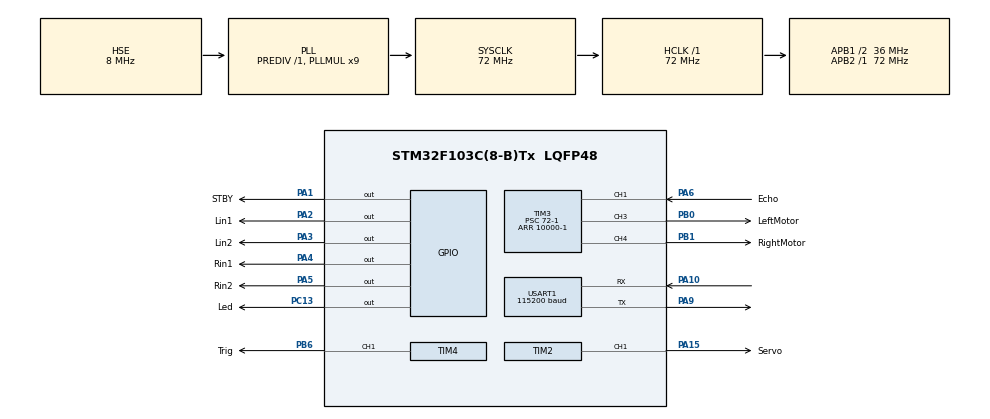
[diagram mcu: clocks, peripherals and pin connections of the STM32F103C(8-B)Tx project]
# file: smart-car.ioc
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Dma.Request0=USART1_TX
Dma.Request1=USART1_RX
Dma.USART1_RX.1.Direction=DMA_PERIPH_TO_MEMORY
Dma.USART1_RX.1.Instance=DMA1_Channel5
Dma.USART1_RX.1.MemDataAlignment=DMA_MDATAALIGN_BYTE
Dma.USART1_RX.1.MemInc=DMA_MINC_ENABLE
Dma.USART1_RX.1.Mode=DMA_NORMAL
Dma.USART1_RX.1.PeriphDataAlignment=DMA_PDATAALIGN_BYTE
Dma.USART1_RX.1.PeriphInc=DMA_PINC_DISABLE
Dma.USART1_RX.1.Priority=DMA_PRIORITY_LOW
Dma.USART1_TX.0.Direction=DMA_MEMORY_TO_PERIPH
Dma.USART1_TX.0.Instance=DMA1_Channel4
Dma.USART1_TX.0.MemDataAlignment=DMA_MDATAALIGN_BYTE
Dma.USART1_TX.0.MemInc=DMA_MINC_ENABLE
Dma.USART1_TX.0.Mode=DMA_NORMAL
Dma.USART1_TX.0.PeriphDataAlignment=DMA_PDATAALIGN_BYTE
Dma.USART1_TX.0.PeriphInc=DMA_PINC_DISABLE
Dma.USART1_TX.0.Priority=DMA_PRIORITY_LOW
FREERTOS.Tasks01=Listen,40,512,ListenInstruction,Default,NULL,Dynamic,NULL,NULL
Mcu.Family=STM32F1
Mcu.Name=STM32F103C(8-B)Tx
Mcu.Package=LQFP48
NVIC.DMA1_Channel4_IRQn=true\:6\:0\:true\:false\:true\:true\:false\:true\:true
NVIC.DMA1_Channel5_IRQn=true\:6\:0\:true\:false\:true\:true\:false\:true\:true
NVIC.PriorityGroup=NVIC_PRIORITYGROUP_4
NVIC.TIM1_UP_IRQn=true\:15\:0\:false\:false\:true\:false\:false\:true\:true
NVIC.TIM3_IRQn=true\:6\:0\:true\:false\:true\:true\:true\:true\:true
NVIC.TimeBase=TIM1_UP_IRQn
NVIC.TimeBaseIP=TIM1
NVIC.USART1_IRQn=true\:6\:0\:true\:false\:true\:true\:true\:true\:true
PA1.GPIO_Label=STBY
PA1.Signal=GPIO_Output
PA10.Mode=Asynchronous
PA10.Signal=USART1_RX
PA13.Mode=Serial_Wire
PA13.Signal=SYS_JTMS-SWDIO
PA14.Mode=Serial_Wire
PA14.Signal=SYS_JTCK-SWCLK
PA15.GPIO_Label=Servo
PA15.Signal=S_TIM2_CH1_ETR
PA2.GPIO_Label=Lin1
PA2.Signal=GPIO_Output
PA3.GPIO_Label=Lin2
PA3.Signal=GPIO_Output
PA4.GPIO_Label=Rin1
PA4.Signal=GPIO_Output
PA5.GPIO_Label=Rin2
PA5.Signal=GPIO_Output
PA6.GPIO_Label=Echo
PA6.Signal=S_TIM3_CH1
PA9.Mode=Asynchronous
PA9.Signal=USART1_TX
PB0.GPIO_Label=LeftMotor
PB0.Signal=S_TIM3_CH3
PB1.GPIO_Label=RightMotor
PB1.Signal=S_TIM3_CH4
PB6.GPIO_Label=Trig
PB6.Signal=S_TIM4_CH1
PC13-TAMPER-RTC.GPIO_Label=Led
PC13-TAMPER-RTC.Signal=GPIO_Output
PD0-OSC_IN.Mode=HSE-External-Oscillator
PD0-OSC_IN.Signal=RCC_OSC_IN
PD1-OSC_OUT.Mode=HSE-External-Oscillator
PD1-OSC_OUT.Signal=RCC_OSC_OUT
ProjectManager.HeapSize=0x200
ProjectManager.StackSize=0x400
ProjectManager.TargetToolchain=STM32CubeIDE
RCC.AHBFreq_Value=72000000
RCC.APB1CLKDivider=RCC_HCLK_DIV2
RCC.APB1Freq_Value=36000000
RCC.APB1TimFreq_Value=72000000
RCC.APB2Freq_Value=72000000
RCC.APB2TimFreq_Value=72000000
RCC.HCLKFreq_Value=72000000
RCC.PLLMUL=RCC_PLL_MUL9
RCC.PLLSourceVirtual=RCC_PLLSOURCE_HSE
RCC.SYSCLKFreq_VALUE=72000000
RCC.SYSCLKSource=RCC_SYSCLKSOURCE_PLLCLK
RCC.USBFreq_Value=72000000
SH.S_TIM2_CH1_ETR.0=TIM2_CH1,PWM Generation1 CH1
SH.S_TIM3_CH1.0=TIM3_CH1,Input_Capture1_from_TI1
SH.S_TIM3_CH3.0=TIM3_CH3,PWM Generation3 CH3
SH.S_TIM3_CH4.0=TIM3_CH4,PWM Generation4 CH4
SH.S_TIM4_CH1.0=TIM4_CH1,PWM Generation1 CH1
TIM2.Channel-PWM\ Generation1\ CH1=TIM_CHANNEL_1
TIM2.OCPolarity_1=TIM_OCPOLARITY_HIGH
TIM2.Period=2000-1
TIM2.Prescaler=720-1
TIM3.Channel-Input_Capture1_from_TI1=TIM_CHANNEL_1
TIM3.Channel-Input_Capture2_from_TI1_63=TIM_CHANNEL_2
TIM3.Channel-PWM\ Generation3\ CH3=TIM_CHANNEL_3
TIM3.Channel-PWM\ Generation4\ CH4=TIM_CHANNEL_4
TIM3.ICPolarity_CH2=TIM_INPUTCHANNELPOLARITY_FALLING
TIM3.Period=10000-1
TIM3.Prescaler=72-1
TIM4.Channel-PWM\ Generation1\ CH1=TIM_CHANNEL_1
TIM4.OCMode_PWM-PWM\ Generation1\ CH1=TIM_OCMODE_PWM2
TIM4.OCPolarity_1=TIM_OCPOLARITY_HIGH
TIM4.Period=10000 -1
TIM4.Prescaler=72 -1
TIM4.Pulse-PWM\ Generation1\ CH1=50
USART1.BaudRate=115200
USART1.VirtualMode=VM_ASYNC
VP_FREERTOS_VS_CMSIS_V2.Mode=CMSIS_V2
VP_SYS_VS_tim1.Mode=TIM1
VP_TIM3_VS_ClockSourceINT.Mode=Internal
VP_TIM3_VS_indirect_ch1.Mode=Input_Capture2_from_TI1_63
VP_TIM4_VS_OPM.Mode=OPM_bit
board=custom

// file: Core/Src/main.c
/* USER CODE BEGIN Header */
/**
  ******************************************************************************
  * @file           : main.c
  * @brief          : Main program body
  ******************************************************************************
  * @attention
  *
  * Copyright (c) 2024 STMicroelectronics.
  * All rights reserved.
  *
  * This software is licensed under terms that can be found in the LICENSE file
  * in the root directory of this software component.
  * If no LICENSE file comes with this software, it is provided AS-IS.
  *
  ******************************************************************************
  */
/* USER CODE END Header */
#include "main.h"
#include "cmsis_os.h"
#include "dma.h"
#include "tim.h"
#include "usart.h"
#include "gpio.h"

/* USER CODE BEGIN Includes */
#include "instruction.h"
/* USER CODE END Includes */

void SystemClock_Config(void);
void MX_FREERTOS_Init(void);

int main(void)
{

  /* MCU Configuration--------------------------------------------------------*/

  /* Reset of all peripherals, Initializes the Flash interface and the Systick. */
  HAL_Init();

  /* Configure the system clock */
  SystemClock_Config();

  /* Initialize all configured peripherals */
  MX_GPIO_Init();
  MX_DMA_Init();
  MX_TIM2_Init();
  MX_TIM3_Init();
  MX_TIM4_Init();
  MX_USART1_UART_Init();
  /* USER CODE BEGIN 2 */
  INSTRUCTION_Init();
  /* USER CODE END 2 */

  /* Init scheduler */
  osKernelInitialize();

  /* Call init function for freertos objects (in cmsis_os2.c) */
  MX_FREERTOS_Init();

  /* Start scheduler */
  osKernelStart();

  /* We should never get here as control is now taken by the scheduler */

  /* Infinite loop */
  while (1)
  {

  }
}

void SystemClock_Config(void)
{
  RCC_OscInitTypeDef RCC_OscInitStruct = {0};
  RCC_ClkInitTypeDef RCC_ClkInitStruct = {0};

  /** Initializes the RCC Oscillators according to the specified parameters
  * in the RCC_OscInitTypeDef structure.
  */
  RCC_OscInitStruct.OscillatorType = RCC_OSCILLATORTYPE_HSE;
  RCC_OscInitStruct.HSEState = RCC_HSE_ON;
  RCC_OscInitStruct.HSEPredivValue = RCC_HSE_PREDIV_DIV1;
  RCC_OscInitStruct.HSIState = RCC_HSI_ON;
  RCC_OscInitStruct.PLL.PLLState = RCC_PLL_ON;
  RCC_OscInitStruct.PLL.PLLSource = RCC_PLLSOURCE_HSE;
  RCC_OscInitStruct.PLL.PLLMUL = RCC_PLL_MUL9;
  if (HAL_RCC_OscConfig(&RCC_OscInitStruct) != HAL_OK)
  {
    Error_Handler();
  }

  /** Initializes the CPU, AHB and APB buses clocks
  */
  RCC_ClkInitStruct.ClockType = RCC_CLOCKTYPE_HCLK|RCC_CLOCKTYPE_SYSCLK
                              |RCC_CLOCKTYPE_PCLK1|RCC_CLOCKTYPE_PCLK2;
  RCC_ClkInitStruct.SYSCLKSource = RCC_SYSCLKSOURCE_PLLCLK;
  RCC_ClkInitStruct.AHBCLKDivider = RCC_SYSCLK_DIV1;
  RCC_ClkInitStruct.APB1CLKDivider = RCC_HCLK_DIV2;
  RCC_ClkInitStruct.APB2CLKDivider = RCC_HCLK_DIV1;

  if (HAL_RCC_ClockConfig(&RCC_ClkInitStruct, FLASH_LATENCY_2) != HAL_OK)
  {
    Error_Handler();
  }
}

void HAL_TIM_PeriodElapsedCallback(TIM_HandleTypeDef *htim)
{
  if (htim->Instance == TIM1) {
    HAL_IncTick();
  }
}

void Error_Handler(void)
{
  __disable_irq();
  while (1)
  {
  }
}

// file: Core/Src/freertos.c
/* USER CODE BEGIN Header */
/**
  ******************************************************************************
  * File Name          : freertos.c
  * Description        : Code for freertos applications
  ******************************************************************************
  * @attention
  *
  * Copyright (c) 2024 STMicroelectronics.
  * All rights reserved.
  *
  * This software is licensed under terms that can be found in the LICENSE file
  * in the root directory of this software component.
  * If no LICENSE file comes with this software, it is provided AS-IS.
  *
  ******************************************************************************
  */
/* USER CODE END Header */

#include "FreeRTOS.h"
#include "task.h"
#include "main.h"
#include "cmsis_os.h"

/* USER CODE BEGIN Includes */
#include <stdio.h>

#include "instruction.h"
/* USER CODE END Includes */

/* Definitions for Listen */
osThreadId_t ListenHandle;
const osThreadAttr_t Listen_attributes = {
  .name = "Listen",
  .stack_size = 512 * 4,
  .priority = (osPriority_t) osPriorityHigh,
};

void ListenInstruction(void *argument);

void MX_FREERTOS_Init(void); /* (MISRA C 2004 rule 8.1) */

void MX_FREERTOS_Init(void) {

  /* Create the thread(s) */
  /* creation of Listen */
  ListenHandle = osThreadNew(ListenInstruction, NULL, &Listen_attributes);

}

void ListenInstruction(void *argument)
{
  /* USER CODE BEGIN ListenInstruction */
  /* Infinite loop */
  INSTRUCTION_Init();
  INSTRUCTION_Listen();
  /* USER CODE END ListenInstruction */
}
